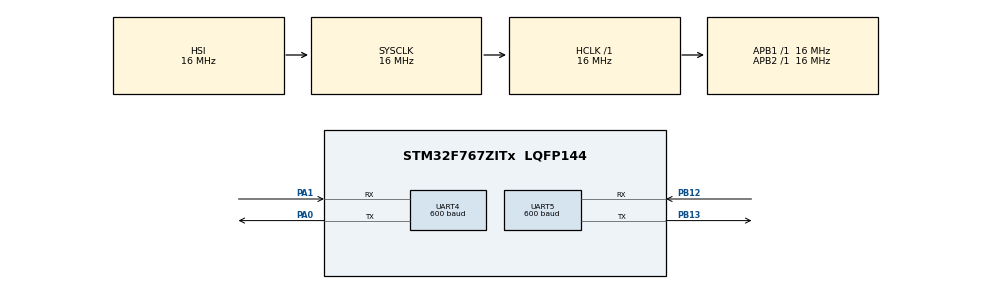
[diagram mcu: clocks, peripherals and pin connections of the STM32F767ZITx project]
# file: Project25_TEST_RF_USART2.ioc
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Mcu.Family=STM32F7
Mcu.Name=STM32F767ZITx
Mcu.Package=LQFP144
NVIC.PriorityGroup=NVIC_PRIORITYGROUP_4
NVIC.UART4_IRQn=true\:0\:0\:false\:false\:true\:true\:true
NVIC.UART5_IRQn=true\:0\:0\:false\:false\:true\:true\:true
PA0/WKUP.Mode=Asynchronous
PA0/WKUP.Signal=UART4_TX
PA1.Mode=Asynchronous
PA1.Signal=UART4_RX
PB12.Mode=Asynchronous
PB12.Signal=UART5_RX
PB13.Mode=Asynchronous
PB13.Signal=UART5_TX
ProjectManager.HeapSize=0x200
ProjectManager.StackSize=0x400
ProjectManager.TargetToolchain=EWARM V8
RCC.48MHZClocksFreq_Value=24000000
RCC.AHBFreq_Value=16000000
RCC.APB1Freq_Value=16000000
RCC.APB1TimFreq_Value=16000000
RCC.APB2Freq_Value=16000000
RCC.APB2TimFreq_Value=16000000
RCC.CortexFreq_Value=16000000
RCC.HCLKFreq_Value=16000000
RCC.HSE_VALUE=16000000
RCC.HSI_VALUE=16000000
RCC.LSE_VALUE=32768
RCC.PLLMUL=RCC_PLL_MUL9
RCC.PRESCALERUSB=RCC_USBCLKSOURCE_PLL_DIV1_5
RCC.SYSCLKFreq_VALUE=16000000
RCC.SYSCLKSourceVirtual=RCC_SYSCLKSOURCE_PLLCLK
RCC.USBFreq_Value=96000000
RCC.VCOOutputFreq_Value=192000000
UART4.BaudRate=600
UART5.BaudRate=600
board=NUCLEO-F767ZI

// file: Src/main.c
/* USER CODE BEGIN Header */
/**
  ******************************************************************************
  * @file           : main.c
  * @brief          : Main program body
  ******************************************************************************
  * @attention
  *
  * <h2><center>&copy; Copyright (c) 2021 STMicroelectronics.
  * All rights reserved.</center></h2>
  *
  * This software component is licensed by ST under BSD 3-Clause license,
  * the "License"; You may not use this file except in compliance with the
  * License. You may obtain a copy of the License at:
  *                        opensource.org/licenses/BSD-3-Clause
  *
  ******************************************************************************
  */
/* USER CODE END Header */

#include "main.h"

UART_HandleTypeDef huart4;
UART_HandleTypeDef huart5;

/* USER CODE BEGIN PV */
uint8_t tx[8]={1, 2, 3, 4, 5, 7, 6, 8};
uint8_t primit[8];
uint8_t primit2[8];
uint8_t ok=0;
/* USER CODE END PV */

void SystemClock_Config(void);
static void MX_GPIO_Init(void);
static void MX_UART4_Init(void);
static void MX_UART5_Init(void);

int main(void)
{

  /* MCU Configuration--------------------------------------------------------*/

  /* Reset of all peripherals, Initializes the Flash interface and the Systick. */
  HAL_Init();

  /* Configure the system clock */
  SystemClock_Config();

  /* Initialize all configured peripherals */
  MX_GPIO_Init();
  MX_UART4_Init();
  MX_UART5_Init();
  /* USER CODE BEGIN 2 */
HAL_UART_Receive_IT(&huart5, primit, 8);
HAL_UART_Receive_IT(&huart4, primit2, 8);
  /* USER CODE END 2 */

  /* Infinite loop */
  while (1)
  {

    /* USER CODE BEGIN 3 */

      HAL_UART_Transmit(&huart4, tx, 8, HAL_MAX_DELAY);

  }
  /* USER CODE END 3 */
}

void SystemClock_Config(void)
{
  RCC_OscInitTypeDef RCC_OscInitStruct = {0};
  RCC_ClkInitTypeDef RCC_ClkInitStruct = {0};
  RCC_PeriphCLKInitTypeDef PeriphClkInitStruct = {0};

  /** Configure the main internal regulator output voltage
  */
  __HAL_RCC_PWR_CLK_ENABLE();
  __HAL_PWR_VOLTAGESCALING_CONFIG(PWR_REGULATOR_VOLTAGE_SCALE3);
  /** Initializes the CPU, AHB and APB busses clocks
  */
  RCC_OscInitStruct.OscillatorType = RCC_OSCILLATORTYPE_HSI;
  RCC_OscInitStruct.HSIState = RCC_HSI_ON;
  RCC_OscInitStruct.HSICalibrationValue = RCC_HSICALIBRATION_DEFAULT;
  RCC_OscInitStruct.PLL.PLLState = RCC_PLL_NONE;
  if (HAL_RCC_OscConfig(&RCC_OscInitStruct) != HAL_OK)
  {
    Error_Handler();
  }
  /** Initializes the CPU, AHB and APB busses clocks
  */
  RCC_ClkInitStruct.ClockType = RCC_CLOCKTYPE_HCLK|RCC_CLOCKTYPE_SYSCLK
                              |RCC_CLOCKTYPE_PCLK1|RCC_CLOCKTYPE_PCLK2;
  RCC_ClkInitStruct.SYSCLKSource = RCC_SYSCLKSOURCE_HSI;
  RCC_ClkInitStruct.AHBCLKDivider = RCC_SYSCLK_DIV1;
  RCC_ClkInitStruct.APB1CLKDivider = RCC_HCLK_DIV1;
  RCC_ClkInitStruct.APB2CLKDivider = RCC_HCLK_DIV1;

  if (HAL_RCC_ClockConfig(&RCC_ClkInitStruct, FLASH_LATENCY_0) != HAL_OK)
  {
    Error_Handler();
  }
  PeriphClkInitStruct.PeriphClockSelection = RCC_PERIPHCLK_UART4|RCC_PERIPHCLK_UART5;
  PeriphClkInitStruct.Uart4ClockSelection = RCC_UART4CLKSOURCE_PCLK1;
  PeriphClkInitStruct.Uart5ClockSelection = RCC_UART5CLKSOURCE_PCLK1;
  if (HAL_RCCEx_PeriphCLKConfig(&PeriphClkInitStruct) != HAL_OK)
  {
    Error_Handler();
  }
}

static void MX_UART4_Init(void)
{

  huart4.Instance = UART4;
  huart4.Init.BaudRate = 600;
  huart4.Init.WordLength = UART_WORDLENGTH_8B;
  huart4.Init.StopBits = UART_STOPBITS_1;
  huart4.Init.Parity = UART_PARITY_NONE;
  huart4.Init.Mode = UART_MODE_TX_RX;
  huart4.Init.HwFlowCtl = UART_HWCONTROL_NONE;
  huart4.Init.OverSampling = UART_OVERSAMPLING_16;
  huart4.Init.OneBitSampling = UART_ONE_BIT_SAMPLE_DISABLE;
  huart4.AdvancedInit.AdvFeatureInit = UART_ADVFEATURE_NO_INIT;
  if (HAL_UART_Init(&huart4) != HAL_OK)
  {
    Error_Handler();
  }

}

static void MX_UART5_Init(void)
{

  huart5.Instance = UART5;
  huart5.Init.BaudRate = 600;
  huart5.Init.WordLength = UART_WORDLENGTH_8B;
  huart5.Init.StopBits = UART_STOPBITS_1;
  huart5.Init.Parity = UART_PARITY_NONE;
  huart5.Init.Mode = UART_MODE_TX_RX;
  huart5.Init.HwFlowCtl = UART_HWCONTROL_NONE;
  huart5.Init.OverSampling = UART_OVERSAMPLING_16;
  huart5.Init.OneBitSampling = UART_ONE_BIT_SAMPLE_DISABLE;
  huart5.AdvancedInit.AdvFeatureInit = UART_ADVFEATURE_NO_INIT;
  if (HAL_UART_Init(&huart5) != HAL_OK)
  {
    Error_Handler();
  }

}

static void MX_GPIO_Init(void)
{

  /* GPIO Ports Clock Enable */
  __HAL_RCC_GPIOA_CLK_ENABLE();
  __HAL_RCC_GPIOB_CLK_ENABLE();

}

void Error_Handler(void)
{
}

/************************ (C) COPYRIGHT STMicroelectronics *****END OF FILE****/
